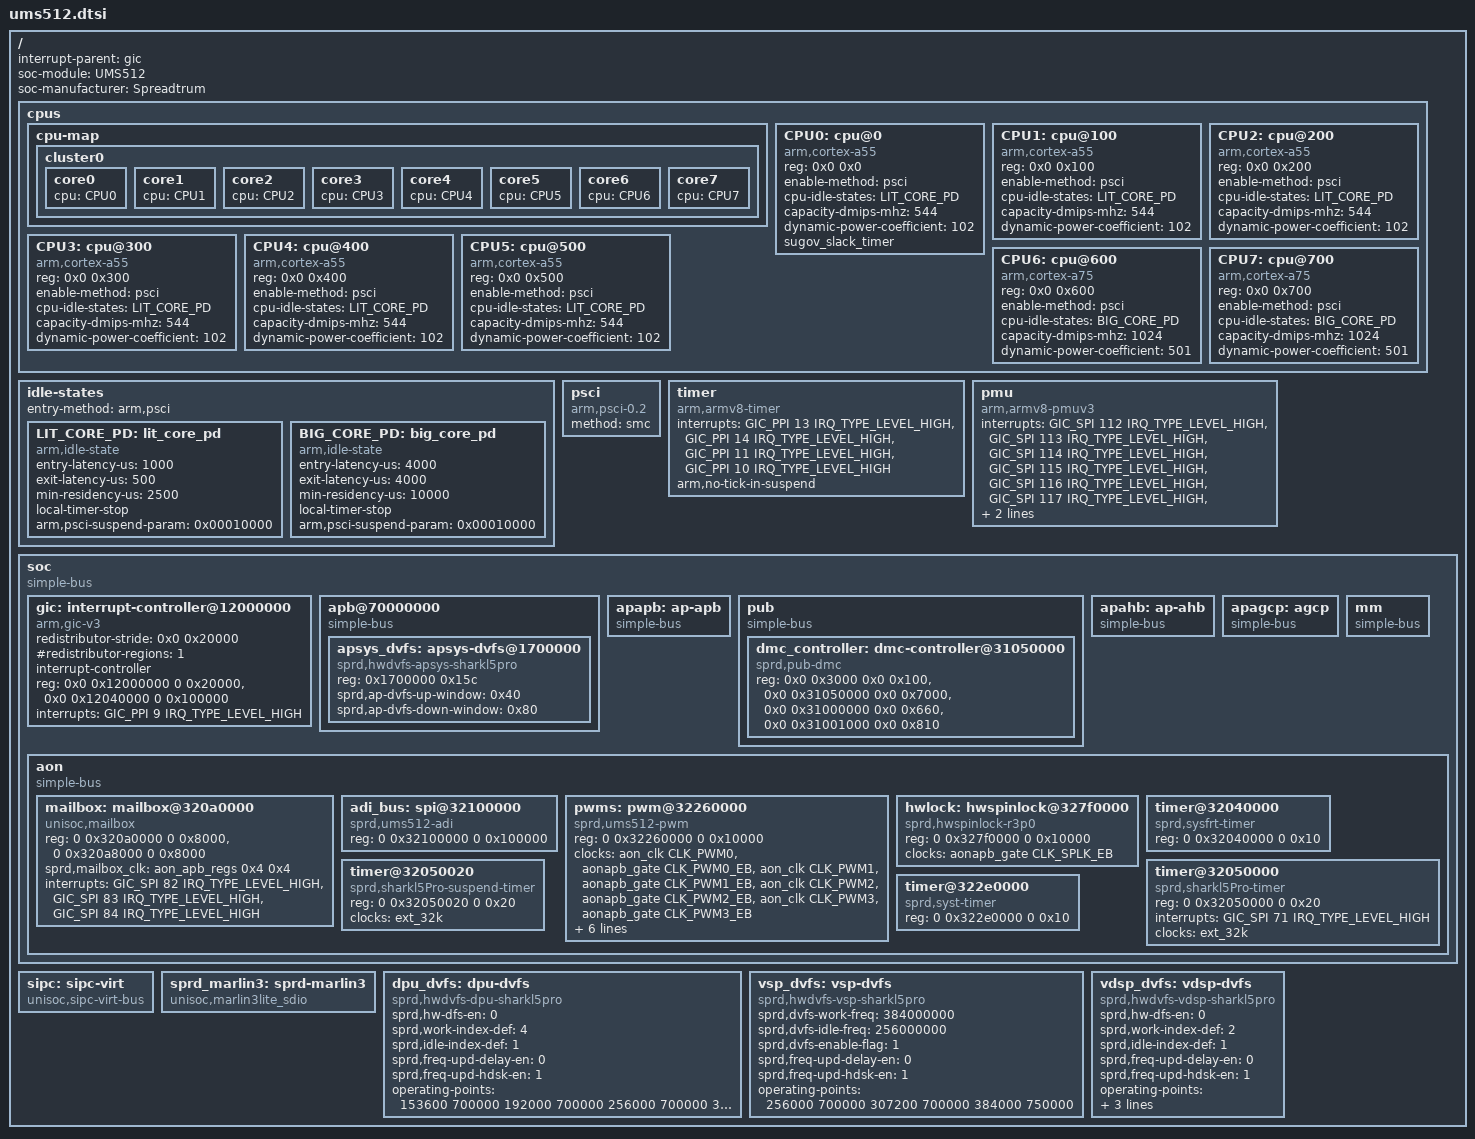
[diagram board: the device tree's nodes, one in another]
// SPDX-License-Identifier: GPL-2.0-only
/*
 * Unisoc UMS512 SoC DTS file
 *
 * Copyright (C) 2021, Unisoc Inc.
 */

#include <dt-bindings/clock/sprd,ums512-clk.h>
#include <dt-bindings/reset/sprd,ums512-reset.h>
#include <dt-bindings/gpio/gpio.h>
#include <dt-bindings/input/input.h>
#include <dt-bindings/interrupt-controller/arm-gic.h>
#include <dt-bindings/mfd/sprd,sc2730-mask.h>
#include <dt-bindings/mfd/sprd,sc2730-regs.h>

/ {
	interrupt-parent = <&gic>;
	#address-cells = <2>;
	#size-cells = <2>;

        soc-module="UMS512";
        soc-manufacturer="Spreadtrum";

	cpus {
		#address-cells = <2>;
		#size-cells = <0>;

		cpu-map {
			cluster0 {
				core0 {
					cpu = <&CPU0>;
				};
				core1 {
					cpu = <&CPU1>;
				};
				core2 {
					cpu = <&CPU2>;
				};
				core3 {
					cpu = <&CPU3>;
				};
				core4 {
					cpu = <&CPU4>;
				};
				core5 {
					cpu = <&CPU5>;
				};
				core6 {
					cpu = <&CPU6>;
				};
				core7 {
					cpu = <&CPU7>;
				};
			};
		};

		CPU0: cpu@0 {
			device_type = "cpu";
			compatible = "arm,cortex-a55";
			reg = <0x0 0x0>;
			enable-method = "psci";
			cpu-idle-states = <&LIT_CORE_PD>;
			capacity-dmips-mhz = <544>;
			#cooling-cells = <2>;
			dynamic-power-coefficient = <102>;
			sugov_slack_timer;
		};

		CPU1: cpu@100 {
			device_type = "cpu";
			compatible = "arm,cortex-a55";
			reg = <0x0 0x100>;
			enable-method = "psci";
			cpu-idle-states = <&LIT_CORE_PD>;
			capacity-dmips-mhz = <544>;
			#cooling-cells = <2>;
			dynamic-power-coefficient = <102>;
		};

		CPU2: cpu@200 {
			device_type = "cpu";
			compatible = "arm,cortex-a55";
			reg = <0x0 0x200>;
			enable-method = "psci";
			cpu-idle-states = <&LIT_CORE_PD>;
			capacity-dmips-mhz = <544>;
			#cooling-cells = <2>;
			dynamic-power-coefficient = <102>;
		};

		CPU3: cpu@300 {
			device_type = "cpu";
			compatible = "arm,cortex-a55";
			reg = <0x0 0x300>;
			enable-method = "psci";
			cpu-idle-states = <&LIT_CORE_PD>;
			capacity-dmips-mhz = <544>;
			#cooling-cells = <2>;
			dynamic-power-coefficient = <102>;
		};

		CPU4: cpu@400 {
			device_type = "cpu";
			compatible = "arm,cortex-a55";
			reg = <0x0 0x400>;
			enable-method = "psci";
			cpu-idle-states = <&LIT_CORE_PD>;
			capacity-dmips-mhz = <544>;
			#cooling-cells = <2>;
			dynamic-power-coefficient = <102>;
		};

		CPU5: cpu@500 {
			device_type = "cpu";
			compatible = "arm,cortex-a55";
			reg = <0x0 0x500>;
			enable-method = "psci";
			cpu-idle-states = <&LIT_CORE_PD>;
			capacity-dmips-mhz = <544>;
			#cooling-cells = <2>;
			dynamic-power-coefficient = <102>;
		};

		CPU6: cpu@600 {
			device_type = "cpu";
			compatible = "arm,cortex-a75";
			reg = <0x0 0x600>;
			enable-method = "psci";
			cpu-idle-states = <&BIG_CORE_PD>;
			capacity-dmips-mhz = <1024>;
			#cooling-cells = <2>;
			dynamic-power-coefficient = <501>;
		};

		CPU7: cpu@700 {
			device_type = "cpu";
			compatible = "arm,cortex-a75";
			reg = <0x0 0x700>;
			enable-method = "psci";
			cpu-idle-states = <&BIG_CORE_PD>;
			capacity-dmips-mhz = <1024>;
			#cooling-cells = <2>;
			dynamic-power-coefficient = <501>;
		};
	};

	idle-states {
		entry-method = "arm,psci";
		LIT_CORE_PD: lit_core_pd {
			compatible = "arm,idle-state";
			entry-latency-us = <1000>;
			exit-latency-us = <500>;
			min-residency-us = <2500>;
			local-timer-stop;
			arm,psci-suspend-param = <0x00010000>;
		};
		BIG_CORE_PD: big_core_pd {
			compatible = "arm,idle-state";
			entry-latency-us = <4000>;
			exit-latency-us = <4000>;
			min-residency-us = <10000>;
			local-timer-stop;
			arm,psci-suspend-param = <0x00010000>;
		};
	};

	psci {
		compatible = "arm,psci-0.2";
		method = "smc";
	};

	timer {
		compatible = "arm,armv8-timer";
		interrupts = <GIC_PPI 13 IRQ_TYPE_LEVEL_HIGH>, /* Physical Secure PPI */
			     <GIC_PPI 14 IRQ_TYPE_LEVEL_HIGH>, /* Physical Non-Secure PPI */
			     <GIC_PPI 11 IRQ_TYPE_LEVEL_HIGH>, /* Virtual PPI */
			     <GIC_PPI 10 IRQ_TYPE_LEVEL_HIGH>; /* Hipervisor PPI */
		arm,no-tick-in-suspend;
	};

	pmu {
		compatible = "arm,armv8-pmuv3";
		interrupts = <GIC_SPI 112 IRQ_TYPE_LEVEL_HIGH>,
			     <GIC_SPI 113 IRQ_TYPE_LEVEL_HIGH>,
			     <GIC_SPI 114 IRQ_TYPE_LEVEL_HIGH>,
			     <GIC_SPI 115 IRQ_TYPE_LEVEL_HIGH>,
			     <GIC_SPI 116 IRQ_TYPE_LEVEL_HIGH>,
			     <GIC_SPI 117 IRQ_TYPE_LEVEL_HIGH>,
			     <GIC_SPI 118 IRQ_TYPE_LEVEL_HIGH>,
			     <GIC_SPI 119 IRQ_TYPE_LEVEL_HIGH>;
	};

	soc: soc {
		compatible = "simple-bus";
		#address-cells = <2>;
		#size-cells = <2>;
		ranges;

		gic: interrupt-controller@12000000 {
			compatible = "arm,gic-v3";
			#interrupt-cells = <3>;
			#address-cells = <2>;
			#size-cells = <2>;
			ranges;
			redistributor-stride = <0x0 0x20000>;	/* 128KB stride */
			#redistributor-regions = <1>;
			interrupt-controller;
			reg = <0x0 0x12000000 0 0x20000>,	/* GICD */
			      <0x0 0x12040000 0 0x100000>;	/* GICR */
			interrupts = <GIC_PPI 9 IRQ_TYPE_LEVEL_HIGH>;
		};

		apb@70000000 {
			compatible = "simple-bus";
			#address-cells = <1>;
			#size-cells = <1>;
			ranges = <0 0x0 0x70000000 0x10000000>;

			apsys_dvfs: apsys-dvfs@1700000 {
				compatible = "sprd,hwdvfs-apsys-sharkl5pro";
				reg = <0x1700000 0x15c>;

				sprd,ap-dvfs-up-window = <0x40>;
				sprd,ap-dvfs-down-window = <0x80>;
			};
		};

		apapb: ap-apb {
			compatible = "simple-bus";
			#address-cells = <2>;
			#size-cells = <2>;
			ranges;
		};

		pub: pub {
			compatible = "simple-bus";
			#address-cells = <2>;
			#size-cells = <2>;
			ranges;

			dmc_controller: dmc-controller@31050000 {
				compatible = "sprd,pub-dmc";
				reg = <0x0 0x3000 0x0 0x100>,	    /* proc_res */
					<0x0 0x31050000 0x0 0x7000>,/* mon_res */
					<0x0 0x31000000 0x0 0x660>, /* dmc_res */
					<0x0 0x31001000 0x0 0x810>; /* phy0/1_res */
			};
		};

		apahb: ap-ahb {
			compatible = "simple-bus";
			#address-cells = <2>;
			#size-cells = <2>;
			ranges;
		};

		apagcp: agcp{
			compatible = "simple-bus";
			#address-cells = <2>;
			#size-cells = <2>;
			ranges;
		};

		mm: mm {
			compatible = "simple-bus";
			#address-cells = <2>;
			#size-cells = <2>;
			ranges;
		};

		aon: aon {
			compatible = "simple-bus";
			#address-cells = <2>;
			#size-cells = <2>;
			ranges;

			mailbox: mailbox@320a0000 {
				compatible = "unisoc,mailbox";
				reg = <0 0x320a0000 0 0x8000>,
				      <0 0x320a8000 0 0x8000>;
				reg-names = "inbox", "outbox";
				sprd,mailbox_clk = <&aon_apb_regs 0x4 0x4>;
				interrupts = <GIC_SPI 82 IRQ_TYPE_LEVEL_HIGH>,
					     <GIC_SPI 83 IRQ_TYPE_LEVEL_HIGH>,
					     <GIC_SPI 84 IRQ_TYPE_LEVEL_HIGH>;
				interrupt-names = "inbox", "outbox", "oob-outbox";
				#mbox-cells = <2>;
			};

			adi_bus: spi@32100000 {
				compatible = "sprd,ums512-adi";
				reg = <0 0x32100000 0 0x100000>;
				#address-cells = <1>;
				#size-cells = <0>;
			};

			pwms: pwm@32260000 {
				compatible = "sprd,ums512-pwm";
				reg = <0 0x32260000 0 0x10000>;
				clock-names = "pwm0", "enable0",
					      "pwm1", "enable1",
						  "pwm2", "enable2",
					      "pwm3", "enable3";
				clocks = <&aon_clk CLK_PWM0>, <&aonapb_gate CLK_PWM0_EB>,
					 <&aon_clk CLK_PWM1>, <&aonapb_gate CLK_PWM1_EB>,
					 <&aon_clk CLK_PWM2>, <&aonapb_gate CLK_PWM2_EB>,
					 <&aon_clk CLK_PWM3>, <&aonapb_gate CLK_PWM3_EB>;
				assigned-clocks = <&aon_clk CLK_PWM0>,
						  <&aon_clk CLK_PWM1>,
						  <&aon_clk CLK_PWM2>,
						  <&aon_clk CLK_PWM3>;
				assigned-clock-parents = <&ext_26m>,
							 <&ext_26m>,
							 <&ext_26m>,
							 <&ext_26m>;
				counter-bits = "10bit",
						"10bit",
						"10bit",
						"10bit";
				#pwm-cells = <2>;
			};

			hwlock: hwspinlock@327f0000 {
				compatible = "sprd,hwspinlock-r3p0";
				reg = <0 0x327f0000 0 0x10000>;
				#hwlock-cells = <1>;
				clock-names = "enable";
				clocks = <&aonapb_gate CLK_SPLK_EB>;
			};

			timer@32040000 {
				compatible = "sprd,sysfrt-timer";
				reg = <0 0x32040000 0 0x10>;
			};

			timer@32050000 {
				compatible = "sprd,sharkl5Pro-timer",
					"sprd,sc9860-timer";
				reg = <0 0x32050000 0 0x20>;
				interrupts = <GIC_SPI 71 IRQ_TYPE_LEVEL_HIGH>;
				clocks = <&ext_32k>;
			};

			timer@32050020 {
				compatible = "sprd,sharkl5Pro-suspend-timer",
					"sprd,sc9860-suspend-timer";
				reg = <0 0x32050020 0 0x20>;
				clocks = <&ext_32k>;
			};

			timer@322e0000 {
				compatible = "sprd,syst-timer";
				reg = <0 0x322e0000 0 0x10>;
			};
		};
	};
	sipc: sipc-virt {
		compatible = "unisoc,sipc-virt-bus";
		#address-cells = <1>;
		#size-cells = <0>;
	};

	sprd_marlin3: sprd-marlin3 {
		compatible = "unisoc,marlin3lite_sdio";
		#address-cells = <1>;
		#size-cells = <0>;
	};

	dpu_dvfs: dpu-dvfs {
		compatible = "sprd,hwdvfs-dpu-sharkl5pro";
		sprd,hw-dfs-en = <0>;
		sprd,work-index-def = <4>;
		sprd,idle-index-def = <1>;
		sprd,freq-upd-delay-en = <0>;
		sprd,freq-upd-hdsk-en = <1>;

		operating-points = <
			/* kHz    uV */
			153600    700000
			192000    700000
			256000    700000
			307200    700000
			384000    750000
			>;
	};

	vsp_dvfs: vsp-dvfs {
		compatible = "sprd,hwdvfs-vsp-sharkl5pro";
		sprd,dvfs-work-freq = <384000000>;
		sprd,dvfs-idle-freq = <256000000>;
		sprd,dvfs-enable-flag = <1>;
		sprd,freq-upd-delay-en = <0>;
		sprd,freq-upd-hdsk-en = <1>;

		operating-points = <
			/* kHz    uV */
			256000    700000
			307200    700000
			384000    750000
			>;
	};

	vdsp_dvfs: vdsp-dvfs {
		compatible = "sprd,hwdvfs-vdsp-sharkl5pro";
		sprd,hw-dfs-en = <0>;
		sprd,work-index-def = <2>;
		sprd,idle-index-def = <1>;
		sprd,freq-upd-delay-en = <0>;
		sprd,freq-upd-hdsk-en = <1>;
		operating-points = <
			/* kHz    uV */
			256000    700000
			384000    700000
			512000    700000
			614400    750000
			768000    750000
			936000    800000
		>;
		clock-names = "vdsp_twpll",
			"vdsp_lpll",
			"vdsp_isppll";
		clocks = <&pll2 CLK_TWPLL>,
			<&pll2 CLK_LPLL>,
			<&pll2 CLK_ISPPLL>;
	};

};

/* Include other IP modules in ALPHABETICAL order */
#include "apb_prot.dtsi"
#include "apcpu-dvfs.dtsi"
#include "bm.dtsi"
#include "cam.dtsi"
#include "coresight.dtsi"
#include "csi.dtsi"
#include "ddr-dfs.dtsi"
#include "dispc.dtsi"
#include "dma.dtsi"
#include "dmc-mpu.dtsi"
#include "efuse.dtsi"
#include "glbreg.dtsi"
#include "gpio.dtsi"
#include "gpu-gondul.dtsi"
#include "i2c.dtsi"
#include "i2s.dtsi"
#include "jpg.dtsi"
#include "marlin3lite.dtsi"
#include "mipi-serdes.dtsi"
#include "modem.dtsi"
#include "pin-controller.dtsi"
#include "audio.dtsi"
#include "power.dtsi"
#include "ptm.dtsi"
#include "pnp.dtsi"
#include "qos.dtsi"
#include "sdio.dtsi"
#include "sensorhub.dtsi"
#include "socid.dtsi"
#include "spi.dtsi"
#include "thermal.dtsi"
#include "uart.dtsi"
#include "usb.dtsi"
#include "vdsp.dtsi"
#include "vsp.dtsi"
#include "wdt.dtsi"
